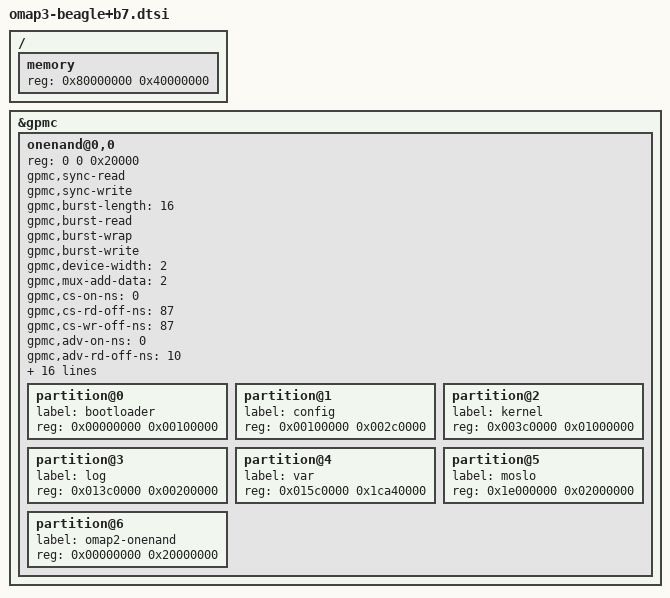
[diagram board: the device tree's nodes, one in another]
/*
 * Copyright (C) 2014 H. Nikolaus Schaller <hns@goldelico.com>
 *
 * This program is free software; you can redistribute it and/or modify
 * it under the terms of the GNU General Public License version 2 as
 * published by the Free Software Foundation.
 *
 * the beagle-b7 is a BeagleBoard plus a display adapter
 * board.
 *
 * This adapter supports
 *   OneNAND
 *   N900 Panel
 *   Backlight driver (GPIO / PWM)
 *   TSC2007 touch screen controller (2C2 + GPIO )
 */

/ {

	memory {
		device_type = "memory";
                reg = <0x80000000 0x40000000>; /* 1 GB */
	};

};

&gpmc {
	ranges = <0 0 0x04000000 0x1000000>;	/* CS0: 16MB for OneNAND */

	onenand@0,0 {
		#address-cells = <1>;
		#size-cells = <1>;
		reg = <0 0 0x20000>;	/* CS0, offset 0, IO size 128K */

		gpmc,sync-read;
		gpmc,sync-write;
		gpmc,burst-length = <16>;
		gpmc,burst-read;
		gpmc,burst-wrap;
		gpmc,burst-write;
		gpmc,device-width = <2>;
		gpmc,mux-add-data = <2>;
		gpmc,cs-on-ns = <0>;
		gpmc,cs-rd-off-ns = <87>;
		gpmc,cs-wr-off-ns = <87>;
		gpmc,adv-on-ns = <0>;
		gpmc,adv-rd-off-ns = <10>;
		gpmc,adv-wr-off-ns = <10>;
		gpmc,oe-on-ns = <15>;
		gpmc,oe-off-ns = <87>;
		gpmc,we-on-ns = <0>;
		gpmc,we-off-ns = <87>;
		gpmc,rd-cycle-ns = <112>;
		gpmc,wr-cycle-ns = <112>;
		gpmc,access-ns = <81>;
		gpmc,page-burst-access-ns = <15>;
		gpmc,bus-turnaround-ns = <0>;
		gpmc,cycle2cycle-delay-ns = <0>;
		gpmc,wait-monitoring-ns = <0>;
		gpmc,clk-activation-ns = <5>;
		gpmc,wr-data-mux-bus-ns = <30>;
		gpmc,wr-access-ns = <81>;
		gpmc,sync-clk-ps = <15000>;

		/*
		 * MTD partition table corresponding to Nokia's MeeGo 1.2
		 * Harmattan release.
		 */
		partition@0 {
			label = "bootloader";
			reg = <0x00000000 0x00100000>;
		};
		partition@1 {
			label = "config";
			reg = <0x00100000 0x002c0000>;
		};
		partition@2 {
			label = "kernel";
			reg = <0x003c0000 0x01000000>;
		};
		partition@3 {
			label = "log";
			reg = <0x013c0000 0x00200000>;
		};
		partition@4 {
			label = "var";
			reg = <0x015c0000 0x1ca40000>;
		};
		partition@5 {
			label = "moslo";
			reg = <0x1e000000 0x02000000>;
		};
		partition@6 {
			label = "omap2-onenand";
			reg = <0x00000000 0x20000000>;
		};
	};
};
